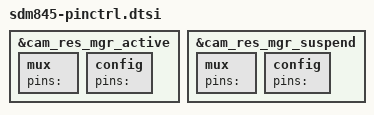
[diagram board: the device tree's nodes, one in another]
&cam_res_mgr_active {
    mux {
        pins = "";
    };
    config {
        pins = "";
    };
};
&cam_res_mgr_suspend {
    mux {
        pins = "";
    };
    config {
        pins = "";
    };
};
